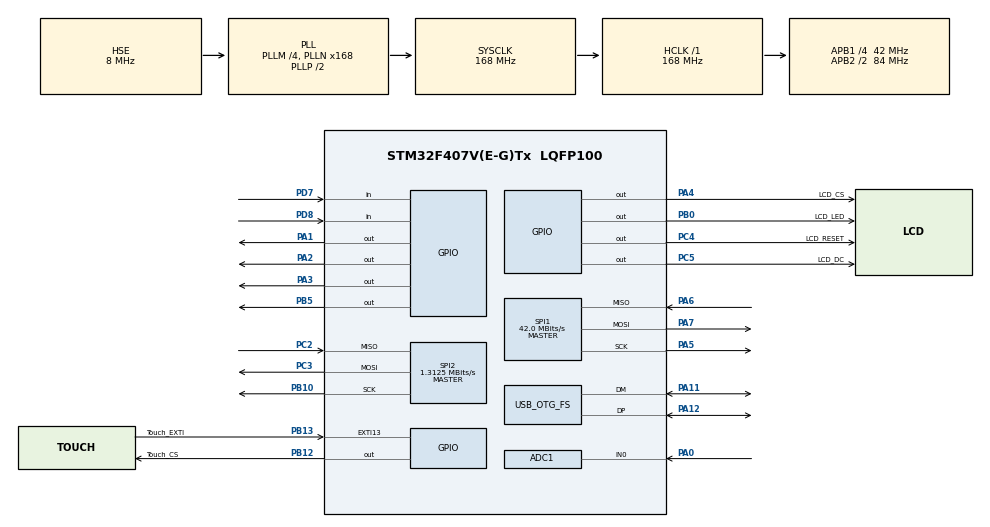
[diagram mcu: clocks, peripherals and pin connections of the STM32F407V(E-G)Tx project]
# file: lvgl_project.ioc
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ADC1.Channel-0\#ChannelRegularConversion=ADC_CHANNEL_0
ADC1.ContinuousConvMode=ENABLE
ADC1.DMAContinuousRequests=ENABLE
ADC1.InjNumberOfConversion=0
ADC1.NbrOfConversion=1
ADC1.NbrOfConversionFlag=1
ADC1.Rank-0\#ChannelRegularConversion=1
ADC1.SamplingTime-0\#ChannelRegularConversion=ADC_SAMPLETIME_480CYCLES
ADC1.ScanConvMode=DISABLE
ADC1.master=1
Dma.ADC1.4.Direction=DMA_PERIPH_TO_MEMORY
Dma.ADC1.4.FIFOMode=DMA_FIFOMODE_DISABLE
Dma.ADC1.4.Instance=DMA2_Stream0
Dma.ADC1.4.MemDataAlignment=DMA_MDATAALIGN_HALFWORD
Dma.ADC1.4.MemInc=DMA_MINC_ENABLE
Dma.ADC1.4.Mode=DMA_CIRCULAR
Dma.ADC1.4.PeriphDataAlignment=DMA_PDATAALIGN_HALFWORD
Dma.ADC1.4.PeriphInc=DMA_PINC_DISABLE
Dma.ADC1.4.Priority=DMA_PRIORITY_LOW
Dma.Request0=SPI1_TX
Dma.Request1=SPI2_RX
Dma.Request2=SPI2_TX
Dma.Request3=SPI1_RX
Dma.Request4=ADC1
Dma.SPI1_RX.3.Direction=DMA_PERIPH_TO_MEMORY
Dma.SPI1_RX.3.FIFOMode=DMA_FIFOMODE_DISABLE
Dma.SPI1_RX.3.Instance=DMA2_Stream2
Dma.SPI1_RX.3.MemDataAlignment=DMA_MDATAALIGN_BYTE
Dma.SPI1_RX.3.MemInc=DMA_MINC_ENABLE
Dma.SPI1_RX.3.Mode=DMA_NORMAL
Dma.SPI1_RX.3.PeriphDataAlignment=DMA_PDATAALIGN_BYTE
Dma.SPI1_RX.3.PeriphInc=DMA_PINC_DISABLE
Dma.SPI1_RX.3.Priority=DMA_PRIORITY_LOW
Dma.SPI1_TX.0.Direction=DMA_MEMORY_TO_PERIPH
Dma.SPI1_TX.0.FIFOMode=DMA_FIFOMODE_DISABLE
Dma.SPI1_TX.0.Instance=DMA2_Stream3
Dma.SPI1_TX.0.MemDataAlignment=DMA_MDATAALIGN_BYTE
Dma.SPI1_TX.0.MemInc=DMA_MINC_ENABLE
Dma.SPI1_TX.0.Mode=DMA_NORMAL
Dma.SPI1_TX.0.PeriphDataAlignment=DMA_PDATAALIGN_BYTE
Dma.SPI1_TX.0.PeriphInc=DMA_PINC_DISABLE
Dma.SPI1_TX.0.Priority=DMA_PRIORITY_LOW
Dma.SPI2_RX.1.Direction=DMA_PERIPH_TO_MEMORY
Dma.SPI2_RX.1.FIFOMode=DMA_FIFOMODE_DISABLE
Dma.SPI2_RX.1.Instance=DMA1_Stream3
Dma.SPI2_RX.1.MemDataAlignment=DMA_MDATAALIGN_BYTE
Dma.SPI2_RX.1.MemInc=DMA_MINC_ENABLE
Dma.SPI2_RX.1.Mode=DMA_NORMAL
Dma.SPI2_RX.1.PeriphDataAlignment=DMA_PDATAALIGN_BYTE
Dma.SPI2_RX.1.PeriphInc=DMA_PINC_DISABLE
Dma.SPI2_RX.1.Priority=DMA_PRIORITY_LOW
Dma.SPI2_TX.2.Direction=DMA_MEMORY_TO_PERIPH
Dma.SPI2_TX.2.FIFOMode=DMA_FIFOMODE_DISABLE
Dma.SPI2_TX.2.Instance=DMA1_Stream4
Dma.SPI2_TX.2.MemDataAlignment=DMA_MDATAALIGN_BYTE
Dma.SPI2_TX.2.MemInc=DMA_MINC_ENABLE
Dma.SPI2_TX.2.Mode=DMA_NORMAL
Dma.SPI2_TX.2.PeriphDataAlignment=DMA_PDATAALIGN_BYTE
Dma.SPI2_TX.2.PeriphInc=DMA_PINC_DISABLE
Dma.SPI2_TX.2.Priority=DMA_PRIORITY_LOW
IWDG.Prescaler=IWDG_PRESCALER_32
IWDG.Reload=3000
Mcu.Family=STM32F4
Mcu.Name=STM32F407V(E-G)Tx
Mcu.Package=LQFP100
NVIC.DMA1_Stream3_IRQn=true\:0\:0\:false\:false\:true\:false\:true\:true
NVIC.DMA1_Stream4_IRQn=true\:0\:0\:false\:false\:true\:false\:true\:true
NVIC.DMA2_Stream0_IRQn=true\:5\:0\:true\:false\:true\:false\:true\:true
NVIC.DMA2_Stream2_IRQn=true\:0\:0\:false\:false\:true\:false\:true\:true
NVIC.DMA2_Stream3_IRQn=true\:0\:0\:false\:false\:true\:false\:true\:true
NVIC.EXTI15_10_IRQn=true\:0\:0\:true\:false\:true\:true\:true\:true
NVIC.OTG_FS_IRQn=true\:0\:0\:false\:false\:true\:false\:true\:true
NVIC.PriorityGroup=NVIC_PRIORITYGROUP_4
NVIC.TIM7_IRQn=true\:1\:0\:true\:false\:true\:false\:true\:true
NVIC.TimeBase=TIM7_IRQn
NVIC.TimeBaseIP=TIM7
PA0-WKUP.Signal=ADCx_IN0
PA1.GPIO_ModeDefaultOutputPP=GPIO_MODE_OUTPUT_OD
PA1.GPIO_PuPd=GPIO_PULLUP
PA1.PinState=GPIO_PIN_SET
PA1.Signal=GPIO_Output
PA11.Mode=Device_Only
PA11.Signal=USB_OTG_FS_DM
PA12.Mode=Device_Only
PA12.Signal=USB_OTG_FS_DP
PA13.Mode=Serial_Wire
PA13.Signal=SYS_JTMS-SWDIO
PA14.Mode=Serial_Wire
PA14.Signal=SYS_JTCK-SWCLK
PA2.GPIO_ModeDefaultOutputPP=GPIO_MODE_OUTPUT_OD
PA2.GPIO_PuPd=GPIO_PULLUP
PA2.GPIO_Speed=GPIO_SPEED_FREQ_VERY_HIGH
PA2.PinState=GPIO_PIN_SET
PA2.Signal=GPIO_Output
PA3.GPIO_ModeDefaultOutputPP=GPIO_MODE_OUTPUT_OD
PA3.GPIO_PuPd=GPIO_PULLUP
PA3.GPIO_Speed=GPIO_SPEED_FREQ_VERY_HIGH
PA3.PinState=GPIO_PIN_SET
PA3.Signal=GPIO_Output
PA4.GPIO_Label=LCD_CS
PA4.Signal=GPIO_Output
PA5.Mode=Full_Duplex_Master
PA5.Signal=SPI1_SCK
PA6.Mode=Full_Duplex_Master
PA6.Signal=SPI1_MISO
PA7.Mode=Full_Duplex_Master
PA7.Signal=SPI1_MOSI
PB0.GPIO_Label=LCD_LED
PB0.Signal=GPIO_Output
PB10.Mode=Full_Duplex_Master
PB10.Signal=SPI2_SCK
PB12.GPIO_Label=Touch_CS
PB12.Signal=GPIO_Output
PB13.GPIO_Label=Touch_EXTI
PB13.GPIO_PuPd=GPIO_PULLUP
PB13.Signal=GPXTI13
PB5.GPIO_ModeDefaultOutputPP=GPIO_MODE_OUTPUT_PP
PB5.GPIO_PuPd=GPIO_PULLDOWN
PB5.Signal=GPIO_Output
PC2.Mode=Full_Duplex_Master
PC2.Signal=SPI2_MISO
PC3.Mode=Full_Duplex_Master
PC3.Signal=SPI2_MOSI
PC4.GPIO_Label=LCD_RESET
PC4.Signal=GPIO_Output
PC5.GPIO_Label=LCD_DC
PC5.Signal=GPIO_Output
PD7.GPIO_PuPd=GPIO_PULLUP
PD7.Signal=GPIO_Input
PD8.GPIO_PuPd=GPIO_PULLUP
PD8.Signal=GPIO_Input
PH0-OSC_IN.Mode=HSE-External-Oscillator
PH0-OSC_IN.Signal=RCC_OSC_IN
PH1-OSC_OUT.Mode=HSE-External-Oscillator
PH1-OSC_OUT.Signal=RCC_OSC_OUT
ProjectManager.HeapSize=0x1000
ProjectManager.StackSize=0x2000
ProjectManager.TargetToolchain=CMake
RCC.48MHZClocksFreq_Value=48000000
RCC.AHBFreq_Value=168000000
RCC.APB1CLKDivider=RCC_HCLK_DIV4
RCC.APB1Freq_Value=42000000
RCC.APB1TimFreq_Value=84000000
RCC.APB2CLKDivider=RCC_HCLK_DIV2
RCC.APB2Freq_Value=84000000
RCC.APB2TimFreq_Value=168000000
RCC.CortexFreq_Value=168000000
RCC.HCLKFreq_Value=168000000
RCC.HSE_VALUE=8000000
RCC.HSI_VALUE=16000000
RCC.LSE_VALUE=32768
RCC.PLLM=4
RCC.PLLN=168
RCC.PLLQ=7
RCC.SYSCLKFreq_VALUE=168000000
RCC.SYSCLKSource=RCC_SYSCLKSOURCE_PLLCLK
RCC.VCOOutputFreq_Value=336000000
SH.ADCx_IN0.0=ADC1_IN0,IN0
SPI1.BaudRatePrescaler=SPI_BAUDRATEPRESCALER_2
SPI1.CalculateBaudRate=42.0 MBits/s
SPI1.DataSize=SPI_DATASIZE_8BIT
SPI1.Direction=SPI_DIRECTION_2LINES
SPI1.Mode=SPI_MODE_MASTER
SPI1.VirtualType=VM_MASTER
SPI2.BaudRatePrescaler=SPI_BAUDRATEPRESCALER_32
SPI2.CalculateBaudRate=1.3125 MBits/s
SPI2.Direction=SPI_DIRECTION_2LINES
SPI2.Mode=SPI_MODE_MASTER
SPI2.VirtualType=VM_MASTER
TIM6.Period=65535
TIM6.Prescaler=84-1
USB_DEVICE.CLASS_NAME_FS=CDC
USB_DEVICE.VirtualMode-CDC_FS=Cdc
USB_DEVICE.VirtualModeFS=Cdc_FS
USB_OTG_FS.VirtualMode=Device_Only
VP_IWDG_VS_IWDG.Mode=IWDG_Activate
VP_SYS_VS_tim7.Mode=TIM7
VP_TIM6_VS_ClockSourceINT.Mode=Enable_Timer
VP_USB_DEVICE_VS_USB_DEVICE_CDC_FS.Mode=CDC_FS
board=custom

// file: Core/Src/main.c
/* USER CODE BEGIN Header */
/**
 ******************************************************************************
 * @file           : main.c
 * @brief          : Main program body
 ******************************************************************************
 * @attention
 *
 * Copyright (c) 2026 STMicroelectronics.
 * All rights reserved.
 *
 * This software is licensed under terms that can be found in the LICENSE file
 * in the root directory of this software component.
 * If no LICENSE file comes with this software, it is provided AS-IS.
 *
 ******************************************************************************
 */
/* USER CODE END Header */
#include "main.h"
#include "adc.h"
#include "dma.h"
#include "iwdg.h"
#include "spi.h"
#include "tim.h"
#include "usb_device.h"
#include "gpio.h"

/* USER CODE BEGIN Includes */
#include "BSP/USB_UART.h"

#include "lvgl/lvgl.h"
#include "lvgl/porting/lv_port_disp.h"
#include "lvgl/porting/lv_port_indev.h"
#include "lvgl/demos/widgets/lv_demo_widgets.h"
#include "lvgl/user/UI/UI.h"

#include "FreeRTOS.h"
#include "task.h"
#include "freertos_dynamic_demo.h"

/* USER CODE END Includes */

/* USER CODE BEGIN PV */
// __attribute__((section(".ccmram"))) static uint8_t lvgl_ccm_heap[48 * 1024];
/* USER CODE END PV */

void SystemClock_Config(void);

int main(void)
{

  /* MCU Configuration--------------------------------------------------------*/

  /* Reset of all peripherals, Initializes the Flash interface and the Systick. */
  HAL_Init();

  /* Configure the system clock */
  SystemClock_Config();

  /* Initialize all configured peripherals */
  MX_GPIO_Init();
  MX_DMA_Init();
  MX_USB_DEVICE_Init();
  MX_SPI1_Init();
  MX_SPI2_Init();
  MX_ADC1_Init();
  MX_TIM6_Init();
  MX_IWDG_Init();
  /* USER CODE BEGIN 2 */

  HAL_TIM_Base_Start(&htim6);   // 手动启动 TIM6 计数器！

  USB_Send_UART("进入FreeRTOS操作系统\n");
  FreeRTOS_Dynamic_Start(); // 进入FreeRTOS操作系统

  /* USER CODE END 2 */

  /* Infinite loop */
  /* USER CODE BEGIN WHILE */
  while (1)
  {
    /* 保底死循环：若程序运行到这里，说明内存（Heap）不足，无法创建 Idle 任务导致启动失败 */
    USB_Send_UART("FreeRTOS堆内存不足");
    HAL_Delay(1000);
    /* USER CODE END WHILE */

  }
}

void SystemClock_Config(void)
{
  RCC_OscInitTypeDef RCC_OscInitStruct = {0};
  RCC_ClkInitTypeDef RCC_ClkInitStruct = {0};

  /** Configure the main internal regulator output voltage
  */
  __HAL_RCC_PWR_CLK_ENABLE();
  __HAL_PWR_VOLTAGESCALING_CONFIG(PWR_REGULATOR_VOLTAGE_SCALE1);

  /** Initializes the RCC Oscillators according to the specified parameters
  * in the RCC_OscInitTypeDef structure.
  */
  RCC_OscInitStruct.OscillatorType = RCC_OSCILLATORTYPE_LSI|RCC_OSCILLATORTYPE_HSE;
  RCC_OscInitStruct.HSEState = RCC_HSE_ON;
  RCC_OscInitStruct.LSIState = RCC_LSI_ON;
  RCC_OscInitStruct.PLL.PLLState = RCC_PLL_ON;
  RCC_OscInitStruct.PLL.PLLSource = RCC_PLLSOURCE_HSE;
  RCC_OscInitStruct.PLL.PLLM = 4;
  RCC_OscInitStruct.PLL.PLLN = 168;
  RCC_OscInitStruct.PLL.PLLP = RCC_PLLP_DIV2;
  RCC_OscInitStruct.PLL.PLLQ = 7;
  if (HAL_RCC_OscConfig(&RCC_OscInitStruct) != HAL_OK)
  {
    Error_Handler();
  }

  /** Initializes the CPU, AHB and APB buses clocks
  */
  RCC_ClkInitStruct.ClockType = RCC_CLOCKTYPE_HCLK|RCC_CLOCKTYPE_SYSCLK
                              |RCC_CLOCKTYPE_PCLK1|RCC_CLOCKTYPE_PCLK2;
  RCC_ClkInitStruct.SYSCLKSource = RCC_SYSCLKSOURCE_PLLCLK;
  RCC_ClkInitStruct.AHBCLKDivider = RCC_SYSCLK_DIV1;
  RCC_ClkInitStruct.APB1CLKDivider = RCC_HCLK_DIV4;
  RCC_ClkInitStruct.APB2CLKDivider = RCC_HCLK_DIV2;

  if (HAL_RCC_ClockConfig(&RCC_ClkInitStruct, FLASH_LATENCY_5) != HAL_OK)
  {
    Error_Handler();
  }
}

void HAL_TIM_PeriodElapsedCallback(TIM_HandleTypeDef *htim)
{
  if (htim->Instance == TIM7)
  {
    HAL_IncTick();
  }
}

void Error_Handler(void)
{
  __disable_irq();
  while (1)
  {
  }
}
